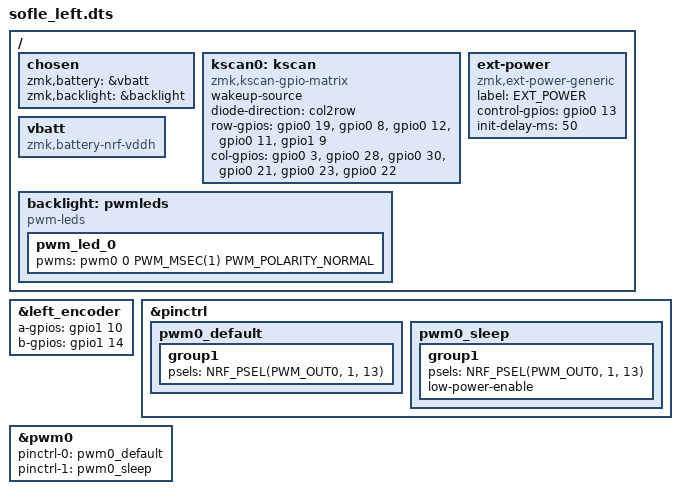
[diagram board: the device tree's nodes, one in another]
/*
*
* Copyright (c) 2021 Darryl deHaan
* SPDX-License-Identifier: MIT
*
*/

#include "sofle.dtsi"
#include <dt-bindings/led/led.h>

/{
    chosen {
        zmk,battery = &vbatt;
        zmk,backlight = &backlight;

    };

    kscan0: kscan {
        compatible = "zmk,kscan-gpio-matrix";
     wakeup-source;
        diode-direction = "col2row";
        row-gpios
            = <&gpio0 19 (GPIO_ACTIVE_HIGH | GPIO_PULL_DOWN)>
            , <&gpio0 8 (GPIO_ACTIVE_HIGH | GPIO_PULL_DOWN)>
            , <&gpio0 12 (GPIO_ACTIVE_HIGH | GPIO_PULL_DOWN)>
            , <&gpio0 11 (GPIO_ACTIVE_HIGH | GPIO_PULL_DOWN)>
            , <&gpio1 9 (GPIO_ACTIVE_HIGH | GPIO_PULL_DOWN)>
            ;

        col-gpios
            = <&gpio0 3 GPIO_ACTIVE_HIGH>
            , <&gpio0 28 GPIO_ACTIVE_HIGH>
            , <&gpio0 30 GPIO_ACTIVE_HIGH>
            , <&gpio0 21 GPIO_ACTIVE_HIGH>
            , <&gpio0 23 GPIO_ACTIVE_HIGH>
            , <&gpio0 22 GPIO_ACTIVE_HIGH>
            ;
    };

    ext-power {
        compatible = "zmk,ext-power-generic";
        label = "EXT_POWER";
        control-gpios = <&gpio0 13 GPIO_ACTIVE_HIGH>;
        init-delay-ms = <50>;
    };

     vbatt: vbatt {
        compatible = "zmk,battery-nrf-vddh";
    };
backlight: pwmleds {
        compatible = "pwm-leds";
        pwm_led_0 {
            pwms = <&pwm0 0 PWM_MSEC(1) PWM_POLARITY_NORMAL>;
        };
    };

};

&left_encoder {
	a-gpios = <&gpio1 10 (GPIO_ACTIVE_HIGH | GPIO_PULL_UP)>;
	b-gpios = <&gpio1 14 (GPIO_ACTIVE_HIGH | GPIO_PULL_UP)>;
    status = "okay";
};
&pinctrl {
    // Other pinctrl definitions for other hardware
    pwm0_default: pwm0_default {
        group1 {
            psels = <NRF_PSEL(PWM_OUT0, 1, 13)>;
        };
    };
    pwm0_sleep: pwm0_sleep {
        group1 {
            psels = <NRF_PSEL(PWM_OUT0, 1, 13)>;
            low-power-enable;
        
        };
    };
};
&pwm0 {
    status = "okay";
    pinctrl-0 = <&pwm0_default>;
    pinctrl-1 = <&pwm0_sleep>;
    pinctrl-names = "default", "sleep";
};

